VERSION ""

NS_ :

BS_:

BU_: Vector__XXX

BO_ 2021 RES_LSS_Rx: 8 Vector__XXX

BO_ 2020 RES_LSS_Tx: 8 Vector__XXX

BO_ 1553 RES_SDO_Rx: 8 Vector__XXX

BO_ 1425 RES_SDO_Tx: 8 Vector__XXX

BO_ 529 RES_PDO_Rx: 8 Vector__XXX

BO_ 256 RES_TimeStamp: 6 Vector__XXX
SG_ TimeOfDay : 0|48@1+ (1,0) [0|281474976710655] "" Vector__XXX

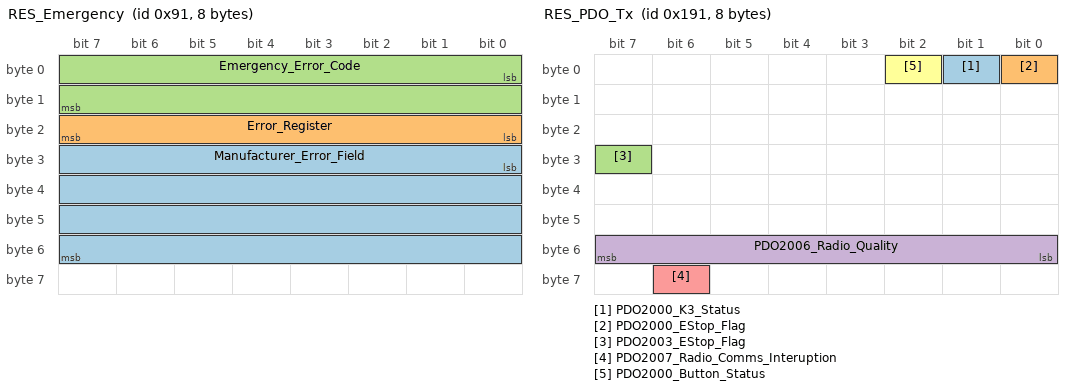
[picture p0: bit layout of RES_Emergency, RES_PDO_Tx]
BO_ 145 RES_Emergency: 8 Vector__XXX
SG_ Manufacturer_Error_Field : 24|32@1+ (1,0) [0|4294967295] "" Vector__XXX
SG_ Error_Register : 16|8@1+ (1,0) [0|255] "" Vector__XXX
SG_ Emergency_Error_Code : 0|16@1+ (1,0) [0|65535] "" Vector__XXX

BO_ 128 RES_Sync: 1 Vector__XXX
SG_ Sync_Counter : 0|8@1+ (1,0) [0|255] "" Vector__XXX

BO_ 1809 RES_NMT_Node_Monitoring: 1 Vector__XXX
SG_ Initialisation_Signalisation : 0|8@1+ (1,0) [0|255] "" Vector__XXX

BO_ 0 RES_NMT_Node_Control: 2 Vector__XXX
SG_ NMT_Node_ID : 8|8@1+ (1,0) [0|255] "" Vector__XXX
SG_ Operational_Mode_Flag : 0|8@1+ (1,0) [0|255] "" Vector__XXX

BO_ 401 RES_PDO_Tx: 8 Vector__XXX
SG_ PDO2000_K3_Status : 1|1@1+ (1,0) [0|1] "" Vector__XXX
SG_ PDO2000_EStop_Flag : 0|1@1+ (1,0) [0|1] "" Vector__XXX
SG_ PDO2003_EStop_Flag : 31|1@1+ (1,0) [0|1] "" Vector__XXX
SG_ PDO2006_Radio_Quality : 48|8@1+ (1,0) [0|255] "%" Vector__XXX
SG_ PDO2007_Radio_Comms_Interuption : 62|1@1+ (1,0) [0|1] "" Vector__XXX
SG_ PDO2000_Button_Status : 2|1@1+ (1,0) [0|1] "" Vector__XXX

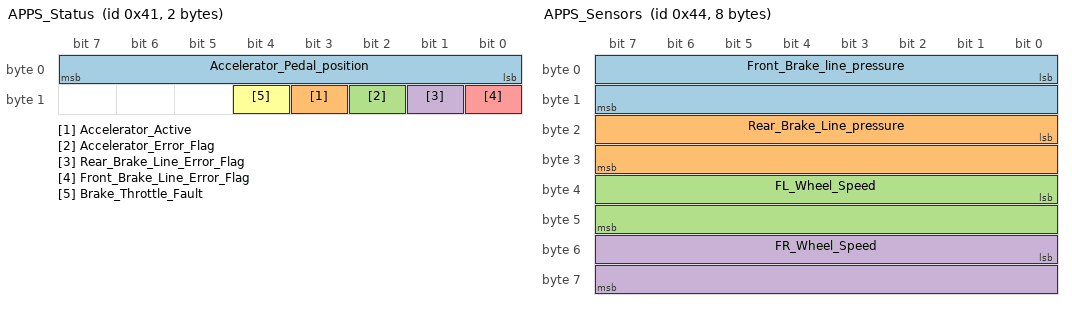
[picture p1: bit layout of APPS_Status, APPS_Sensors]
BO_ 65 APPS_Status: 2 Vector__XXX
SG_ Accelerator_Pedal_position : 0|8@1+ (1,0) [0|255] "%" Vector__XXX
SG_ Accelerator_Active : 11|1@1+ (1,0) [0|1] "" Vector__XXX
SG_ Accelerator_Error_Flag : 10|1@1+ (1,0) [0|1] "" Vector__XXX
SG_ Rear_Brake_Line_Error_Flag : 9|1@1+ (1,0) [0|1] "" Vector__XXX
SG_ Front_Brake_Line_Error_Flag : 8|1@1+ (1,0) [0|1] "" Vector__XXX
SG_ Brake_Throttle_Fault : 12|1@1+ (1,0) [0|1] "" Vector__XXX

BO_ 68 APPS_Sensors: 8 Vector__XXX
SG_ Front_Brake_line_pressure : 0|16@1+ (1,0) [0|32767] "bar" Vector__XXX
SG_ Rear_Brake_Line_pressure : 16|16@1+ (1,0) [0|65535] "bar" Vector__XXX
SG_ FL_Wheel_Speed : 32|16@1+ (0.1,0) [0|6553.5] "rpm" Vector__XXX
SG_ FR_Wheel_Speed : 48|16@1+ (0.1,0) [0|6553.5] "rpm" Vector__XXX

BO_ 66 VCUIO_Wheel_Speeds: 4 Vector__XXX
SG_ RL_Wheel_Speed : 0|16@1+ (0.1,0) [0|6553.5] "rpm" Vector__XXX
SG_ RR_Wheel_Speed : 16|16@1+ (0.1,0) [0|6553.5] "rpm" Vector__XXX

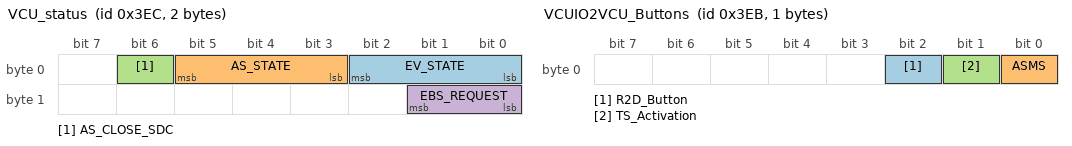
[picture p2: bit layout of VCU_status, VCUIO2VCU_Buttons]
BO_ 1004 VCU_status: 2 Vector__XXX
SG_ EV_STATE : 0|3@1+ (1,0) [0|7] "" Vector__XXX
SG_ AS_STATE : 3|3@1+ (1,0) [0|7] "" Vector__XXX
SG_ AS_CLOSE_SDC : 6|1@1+ (1,0) [0|1] "" Vector__XXX
SG_ EBS_REQUEST : 8|2@1+ (1,0) [0|3] "" Vector__XXX

BO_ 513 Inverter_Snd: 4 Vector__XXX
SG_ Inverter_Snd_Mux M : 0|8@1+ (1,0) [0|0] "" Vector__XXX
SG_ Speed_Request m49 : 8|8@1- (1,0) [-128|127] "" Vector__XXX
SG_ Torque_Request m144 : 8|8@1- (1,0) [-128|127] "" Vector__XXX
SG_ Set_kern_mode m81 : 8|8@1- (1,0) [-128|127] "" Vector__XXX
SG_ Read_cmd m61 : 8|8@1- (1,0) [-128|127] "" Vector__XXX

BO_ 385 Inveter_Rcv: 4 Vector__XXX
SG_ Inveter_Rcv_Mux M : 0|8@1+ (1,0) [0|0] "" Vector__XXX
SG_ Actual_Torque m160 : 8|8@1- (1,0) [-128|127] "" Vector__XXX
SG_ IO_Bitmap m216 : 8|16@1- (1,0) [-32768|32767] "" Vector__XXX
SG_ GO_Drive_Enabled m227 : 8|1@1+ (1,0) [0|1] "" Vector__XXX
SG_ RDY m226 : 8|1@1+ (1,0) [0|1] "" Vector__XXX
SG_ RUN m232 : 8|1@1+ (1,0) [0|1] "" Vector__XXX
SG_ N_Actual m48 : 8|16@1- (1,0) [0|255] "" Vector__XXX
SG_ Kern_Mode m81 : 8|8@1- (1,0) [-128|127] "" Vector__XXX

BO_ 1003 VCUIO2VCU_Buttons: 1 Vector__XXX
SG_ R2D_Button : 2|1@1+ (1,0) [0|1] "" Vector__XXX
SG_ ASMS : 0|1@1+ (1,0) [0|1] "" Vector__XXX
SG_ TS_Activation : 1|1@1+ (1,0) [0|1] "" Vector__XXX

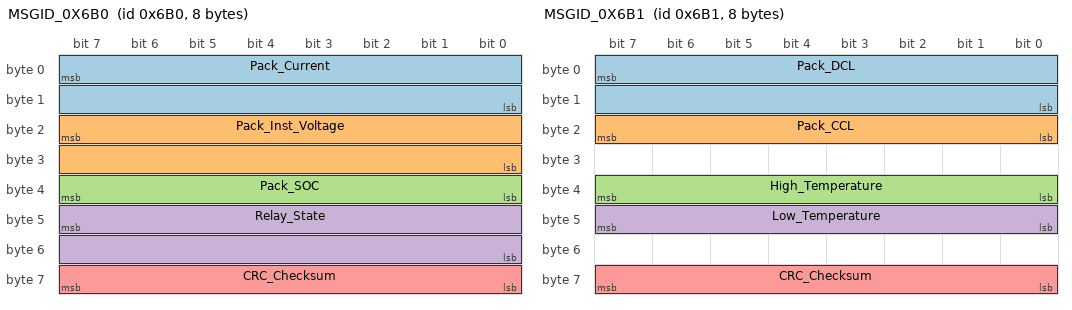
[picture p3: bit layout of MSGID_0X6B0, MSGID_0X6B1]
BO_ 1712 MSGID_0X6B0: 8 Vector__XXX
SG_ Pack_Current : 7|16@0+ (0.1,0) [0|6553.5] "Amps" Vector__XXX
SG_ Pack_Inst_Voltage : 23|16@0+ (0.1,0) [0|6553.5] "Volts" Vector__XXX
SG_ Pack_SOC : 39|8@0+ (0.5,0) [0|127.5] "Percent" Vector__XXX
SG_ Relay_State : 47|16@0+ (1,0) [0|65535] "" Vector__XXX
SG_ CRC_Checksum : 63|8@0+ (1,1720) [1720|1720] "" Vector__XXX

BO_ 1713 MSGID_0X6B1: 8 Vector__XXX
SG_ Pack_DCL : 7|16@0+ (1,0) [0|65535] "Amps" Vector__XXX
SG_ Pack_CCL : 23|8@0+ (1,0) [0|255] "Amps" Vector__XXX
SG_ High_Temperature : 39|8@0+ (1,0) [0|255] "Celsius" Vector__XXX
SG_ Low_Temperature : 47|8@0+ (1,0) [0|255] "Celsius" Vector__XXX
SG_ CRC_Checksum : 63|8@0+ (1,1721) [1721|1721] "" Vector__XXX

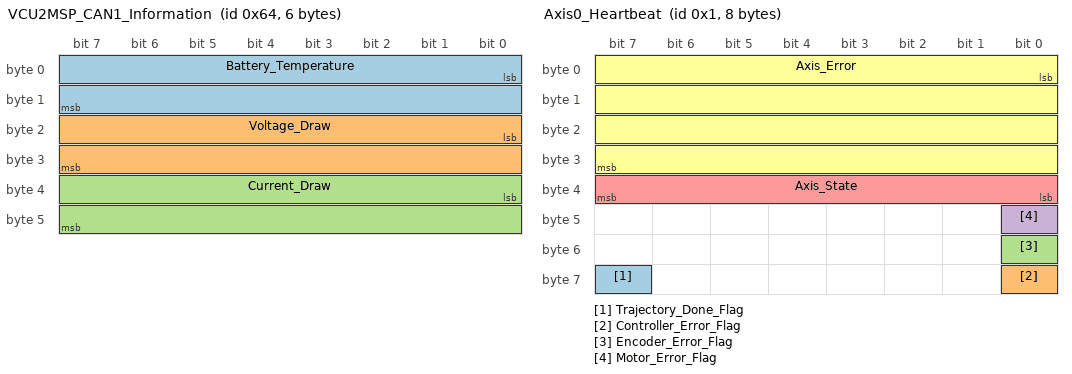
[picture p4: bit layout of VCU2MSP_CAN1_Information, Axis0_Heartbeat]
BO_ 100 VCU2MSP_CAN1_Information: 6 Vector__XXX
SG_ Battery_Temperature : 0|16@1- (1,0) [-32768|32767] "degC" Vector__XXX
SG_ Voltage_Draw : 16|16@1- (0.1,0) [-3276.8|3276.7] "V" Vector__XXX
SG_ Current_Draw : 32|16@1- (0.1,0) [-3276.8|3276.7] "A" Vector__XXX

BO_ 64 MSP2VCU_Status: 1 Vector__XXX
SG_ AMI_STATE : 0|4@1+ (1,0) [0|15] "" Vector__XXX

BO_ 1 Axis0_Heartbeat: 8 Vector__XXX
SG_ Trajectory_Done_Flag : 63|1@1+ (1,0) [0|1] "" Vector__XXX
SG_ Controller_Error_Flag : 56|1@1+ (1,0) [0|1] "" Vector__XXX
SG_ Encoder_Error_Flag : 48|1@1+ (1,0) [0|1] "" Vector__XXX
SG_ Motor_Error_Flag : 40|1@1+ (1,0) [0|1] "" Vector__XXX
SG_ Axis_State : 32|8@1+ (1,0) [0|255] "" Vector__XXX
SG_ Axis_Error : 0|32@1+ (1,0) [0|4294967295] "" Vector__XXX

BO_ 3 Axis0_Get_Motor_Error: 8 Vector__XXX
SG_ Motor_Error : 0|32@1+ (1,0) [0|4294967295] "" Vector__XXX

BO_ 4 Axis0_Get_Encoder_Error: 8 Vector__XXX
SG_ Encoder_Error : 0|32@1+ (1,0) [0|4294967295] "" Vector__XXX

BO_ 5 Axis0_Get_Sensorless_Error: 8 Vector__XXX
SG_ Sensorless_Error : 0|32@1+ (1,0) [0|4294967295] "" Vector__XXX

BO_ 6 Axis0_Set_Axis_Node_ID: 8 Vector__XXX
SG_ Axis_Node_ID : 0|32@1+ (1,0) [0|4294967295] "" Vector__XXX

BO_ 7 Axis0_Set_Axis_State: 8 Vector__XXX
SG_ Axis_Requested_State : 0|32@1+ (1,0) [0|4294967295] "" Vector__XXX

BO_ 9 Axis0_Get_Encoder_Estimates: 8 Vector__XXX
SG_ Vel_Estimate : 32|32@1- (1,0) [-3.4E038|3.4E038] "rev/s" Vector__XXX
SG_ Pos_Estimate : 0|32@1- (1,0) [-3.4E038|3.4E038] "rev" Vector__XXX

BO_ 10 Axis0_Get_Encoder_Count: 8 Vector__XXX
SG_ Count_in_CPR : 32|32@1+ (1,0) [0|4294967295] "counts" Vector__XXX
SG_ Shadow_Count : 0|32@1+ (1,0) [0|4294967295] "counts" Vector__XXX

BO_ 11 Axis0_Set_Controller_Mode: 8 Vector__XXX
SG_ Input_Mode : 32|32@1+ (1,0) [0|4294967295] "" Vector__XXX
SG_ Control_Mode : 0|32@1+ (1,0) [0|4294967295] "" Vector__XXX

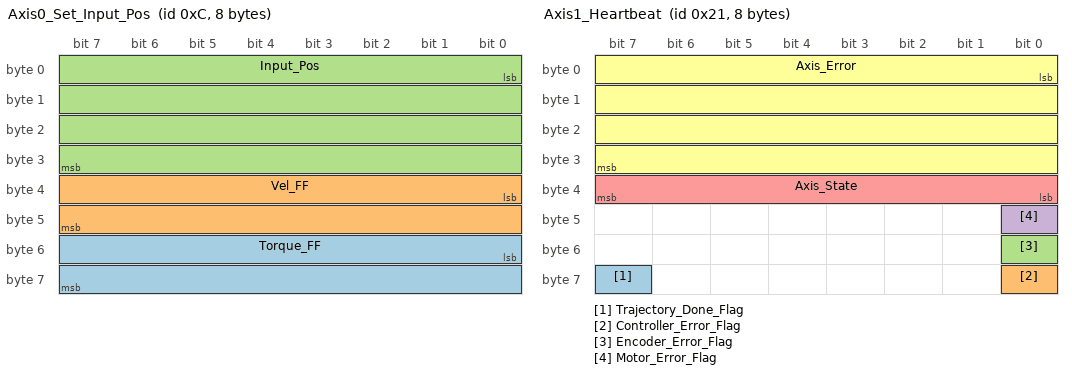
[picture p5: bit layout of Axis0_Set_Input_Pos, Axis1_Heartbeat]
BO_ 12 Axis0_Set_Input_Pos: 8 Vector__XXX
SG_ Torque_FF : 48|16@1- (0.001,0) [-32.768|32.767] "Nm" Vector__XXX
SG_ Vel_FF : 32|16@1- (0.001,0) [-32.768|32.767] "rev/s" Vector__XXX
SG_ Input_Pos : 0|32@1- (1,0) [-3.4E038|3.4E038] "rev" Vector__XXX

BO_ 13 Axis0_Set_Input_Vel: 8 Vector__XXX
SG_ Input_Torque_FF : 32|32@1- (1,0) [-3.4E038|3.4E038] "rev/s" Vector__XXX
SG_ Input_Vel : 0|32@1- (1,0) [-3.4E038|3.4E038] "rev" Vector__XXX

BO_ 14 Axis0_Set_Input_Torque: 8 Vector__XXX
SG_ Input_Torque : 0|32@1- (1,0) [-3.4E038|3.4E038] "Nm" Vector__XXX

BO_ 15 Axis0_Set_Limits: 8 Vector__XXX
SG_ Current_Limit : 32|32@1- (1,0) [-3.4E038|3.4E038] "A" Vector__XXX
SG_ Velocity_Limit : 0|32@1- (1,0) [-3.4E038|3.4E038] "rev/s" Vector__XXX

BO_ 16 Axis0_Start_Anticogging: 0 Vector__XXX

BO_ 17 Axis0_Set_Traj_Vel_Limit: 8 Vector__XXX
SG_ Traj_Vel_Limit : 0|32@1- (1,0) [-3.4E038|3.4E038] "rev/s" Vector__XXX

BO_ 18 Axis0_Set_Traj_Accel_Limits: 8 Vector__XXX
SG_ Traj_Decel_Limit : 32|32@1- (1,0) [-3.4E038|3.4E038] "rev/s^2" Vector__XXX
SG_ Traj_Accel_Limit : 0|32@1- (1,0) [-3.4E038|3.4E038] "rev/s^2" Vector__XXX

BO_ 19 Axis0_Set_Traj_Inertia: 8 Vector__XXX
SG_ Traj_Inertia : 0|32@1- (1,0) [-3.4E038|3.4E038] "Nm / (rev/s^2)" Vector__XXX

BO_ 20 Axis0_Get_Iq: 8 Vector__XXX
SG_ Iq_Measured : 32|32@1- (1,0) [-3.4E038|3.4E038] "A" Vector__XXX
SG_ Iq_Setpoint : 0|32@1- (1,0) [-3.4E038|3.4E038] "A" Vector__XXX

BO_ 21 Axis0_Get_Sensorless_Estimates: 8 Vector__XXX
SG_ Sensorless_Vel_Estimate : 32|32@1- (1,0) [-3.4E038|3.4E038] "rev/s" Vector__XXX
SG_ Sensorless_Pos_Estimate : 0|32@1- (1,0) [-3.4E038|3.4E038] "rev" Vector__XXX

BO_ 22 Axis0_Reboot: 0 Vector__XXX

BO_ 23 Axis0_Get_Bus_Voltage_Current: 8 Vector__XXX
SG_ Bus_Current : 32|32@1- (1,0) [-3.4E038|3.4E038] "A" Vector__XXX
SG_ Bus_Voltage : 0|32@1- (1,0) [-3.4E038|3.4E038] "V" Vector__XXX

BO_ 24 Axis0_Clear_Errors: 0 Vector__XXX

BO_ 25 Axis0_Set_Linear_Count: 8 Vector__XXX
SG_ Position : 0|32@1- (1,0) [-2147483648|2147483647] "counts" Vector__XXX

BO_ 26 Axis0_Set_Pos_Gain: 8 Vector__XXX
SG_ Pos_Gain : 0|32@1- (1,0) [-3.4E038|3.4E038] "(rev/s) / rev" Vector__XXX

BO_ 27 Axis0_Set_Vel_Gains: 8 Vector__XXX
SG_ Vel_Integrator_Gain : 32|32@1- (1,0) [-3.4E038|3.4E038] "(Nm / (rev/s)) /" Vector__XXX
SG_ Vel_Gain : 0|32@1- (1,0) [-3.4E038|3.4E038] "Nm / (rev/s)" Vector__XXX

BO_ 28 Axis0_Get_ADC_Voltage: 8 Vector__XXX
SG_ ADC_Voltage : 0|32@1- (1,0) [-3.4E038|3.4E038] "V" Vector__XXX

BO_ 29 Axis0_Get_Controller_Error: 8 Vector__XXX
SG_ Controller_Error : 0|32@1+ (1,0) [0|4294967295] "" Vector__XXX

BO_ 33 Axis1_Heartbeat: 8 Vector__XXX
SG_ Trajectory_Done_Flag : 63|1@1+ (1,0) [0|1] "" Vector__XXX
SG_ Controller_Error_Flag : 56|1@1+ (1,0) [0|1] "" Vector__XXX
SG_ Encoder_Error_Flag : 48|1@1+ (1,0) [0|1] "" Vector__XXX
SG_ Motor_Error_Flag : 40|1@1+ (1,0) [0|1] "" Vector__XXX
SG_ Axis_State : 32|8@1+ (1,0) [0|255] "" Vector__XXX
SG_ Axis_Error : 0|32@1+ (1,0) [0|4294967295] "" Vector__XXX

BO_ 35 Axis1_Get_Motor_Error: 8 Vector__XXX
SG_ Motor_Error : 0|32@1+ (1,0) [0|4294967295] "" Vector__XXX

BO_ 36 Axis1_Get_Encoder_Error: 8 Vector__XXX
SG_ Encoder_Error : 0|32@1+ (1,0) [0|4294967295] "" Vector__XXX

BO_ 37 Axis1_Get_Sensorless_Error: 8 Vector__XXX
SG_ Sensorless_Error : 0|32@1+ (1,0) [0|4294967295] "" Vector__XXX

BO_ 38 Axis1_Set_Axis_Node_ID: 8 Vector__XXX
SG_ Axis_Node_ID : 0|32@1+ (1,0) [0|4294967295] "" Vector__XXX

BO_ 39 Axis1_Set_Axis_State: 8 Vector__XXX
SG_ Axis_Requested_State : 0|32@1+ (1,0) [0|4294967295] "" Vector__XXX

BO_ 41 Axis1_Get_Encoder_Estimates: 8 Vector__XXX
SG_ Vel_Estimate : 32|32@1- (1,0) [-3.4E038|3.4E038] "rev/s" Vector__XXX
SG_ Pos_Estimate : 0|32@1- (1,0) [-3.4E038|3.4E038] "rev" Vector__XXX

BO_ 42 Axis1_Get_Encoder_Count: 8 Vector__XXX
SG_ Count_in_CPR : 32|32@1+ (1,0) [0|4294967295] "counts" Vector__XXX
SG_ Shadow_Count : 0|32@1+ (1,0) [0|4294967295] "counts" Vector__XXX

BO_ 43 Axis1_Set_Controller_Mode: 8 Vector__XXX
SG_ Input_Mode : 32|32@1+ (1,0) [0|4294967295] "" Vector__XXX
SG_ Control_Mode : 0|32@1+ (1,0) [0|4294967295] "" Vector__XXX

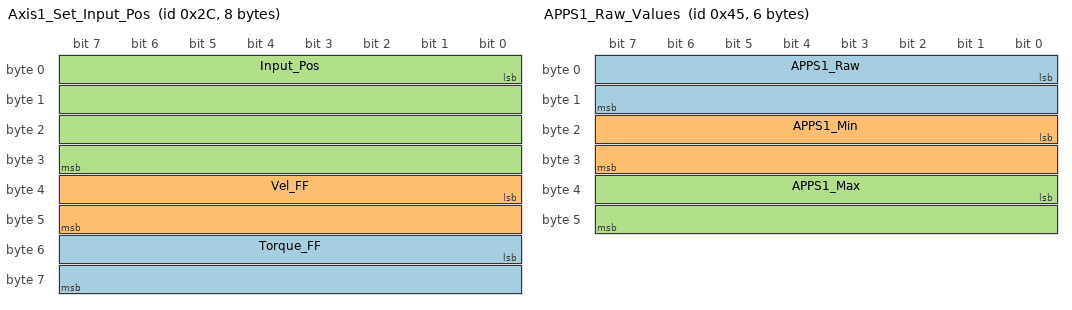
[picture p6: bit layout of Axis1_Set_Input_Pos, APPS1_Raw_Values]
BO_ 44 Axis1_Set_Input_Pos: 8 Vector__XXX
SG_ Torque_FF : 48|16@1- (0.001,0) [-32.768|32.767] "Nm" Vector__XXX
SG_ Vel_FF : 32|16@1- (0.001,0) [-32.768|32.767] "rev/s" Vector__XXX
SG_ Input_Pos : 0|32@1- (1,0) [-3.4E038|3.4E038] "rev" Vector__XXX

BO_ 45 Axis1_Set_Input_Vel: 8 Vector__XXX
SG_ Input_Torque_FF : 32|32@1- (1,0) [-3.4E038|3.4E038] "rev/s" Vector__XXX
SG_ Input_Vel : 0|32@1- (1,0) [-3.4E038|3.4E038] "rev" Vector__XXX

BO_ 46 Axis1_Set_Input_Torque: 8 Vector__XXX
SG_ Input_Torque : 0|32@1- (1,0) [-3.4E038|3.4E038] "Nm" Vector__XXX

BO_ 47 Axis1_Set_Limits: 8 Vector__XXX
SG_ Current_Limit : 32|32@1- (1,0) [-3.4E038|3.4E038] "A" Vector__XXX
SG_ Velocity_Limit : 0|32@1- (1,0) [-3.4E038|3.4E038] "rev/s" Vector__XXX

BO_ 48 Axis1_Start_Anticogging: 0 Vector__XXX

BO_ 49 Axis1_Set_Traj_Vel_Limit: 8 Vector__XXX
SG_ Traj_Vel_Limit : 0|32@1- (1,0) [-3.4E038|3.4E038] "rev/s" Vector__XXX

BO_ 50 Axis1_Set_Traj_Accel_Limits: 8 Vector__XXX
SG_ Traj_Decel_Limit : 32|32@1- (1,0) [-3.4E038|3.4E038] "rev/s^2" Vector__XXX
SG_ Traj_Accel_Limit : 0|32@1- (1,0) [-3.4E038|3.4E038] "rev/s^2" Vector__XXX

BO_ 51 Axis1_Set_Traj_Inertia: 8 Vector__XXX
SG_ Traj_Inertia : 0|32@1- (1,0) [-3.4E038|3.4E038] "Nm / (rev/s^2)" Vector__XXX

BO_ 52 Axis1_Get_Iq: 8 Vector__XXX
SG_ Iq_Measured : 32|32@1- (1,0) [-3.4E038|3.4E038] "A" Vector__XXX
SG_ Iq_Setpoint : 0|32@1- (1,0) [-3.4E038|3.4E038] "A" Vector__XXX

BO_ 53 Axis1_Get_Sensorless_Estimates: 8 Vector__XXX
SG_ Sensorless_Vel_Estimate : 32|32@1- (1,0) [-3.4E038|3.4E038] "rev/s" Vector__XXX
SG_ Sensorless_Pos_Estimate : 0|32@1- (1,0) [-3.4E038|3.4E038] "rev" Vector__XXX

BO_ 54 Axis1_Reboot: 0 Vector__XXX

BO_ 55 Axis1_Get_Bus_Voltage_Current: 8 Vector__XXX
SG_ Bus_Current : 32|32@1- (1,0) [-3.4E038|3.4E038] "A" Vector__XXX
SG_ Bus_Voltage : 0|32@1- (1,0) [-3.4E038|3.4E038] "V" Vector__XXX

BO_ 56 Axis1_Clear_Errors: 0 Vector__XXX

BO_ 57 Axis1_Set_Linear_Count: 8 Vector__XXX
SG_ Position : 0|32@1- (1,0) [-2147483648|2147483647] "counts" Vector__XXX

BO_ 58 Axis1_Set_Pos_Gain: 8 Vector__XXX
SG_ Pos_Gain : 0|32@1- (1,0) [-3.4E038|3.4E038] "(rev/s) / rev" Vector__XXX

BO_ 59 Axis1_Set_Vel_Gains: 8 Vector__XXX
SG_ Vel_Integrator_Gain : 32|32@1- (1,0) [-3.4E038|3.4E038] "(Nm / (rev/s)) /" Vector__XXX
SG_ Vel_Gain : 0|32@1- (1,0) [-3.4E038|3.4E038] "Nm / (rev/s)" Vector__XXX

BO_ 60 Axis1_Get_ADC_Voltage: 8 Vector__XXX
SG_ ADC_Voltage : 0|32@1- (1,0) [-3.4E038|3.4E038] "V" Vector__XXX

BO_ 61 Axis1_Get_Controller_Error: 8 Vector__XXX
SG_ Controller_Error : 0|32@1+ (1,0) [0|4294967295] "" Vector__XXX

BO_ 67 APPS_Config: 1 Vector__XXX
SG_ APPS_RAW_ENABLE : 0|1@1+ (1,0) [0|1] "" Vector__XXX
SG_ SERIAL_DEBUG_ENABLE : 1|1@1+ (1,0) [0|1] "" Vector__XXX

BO_ 69 APPS1_Raw_Values: 6 Vector__XXX
SG_ APPS1_Raw : 0|16@1+ (1,0) [0|65535] "" Vector__XXX
SG_ APPS1_Min : 16|16@1+ (1,0) [0|65535] "" Vector__XXX
SG_ APPS1_Max : 32|16@1+ (1,0) [0|65535] "" Vector__XXX

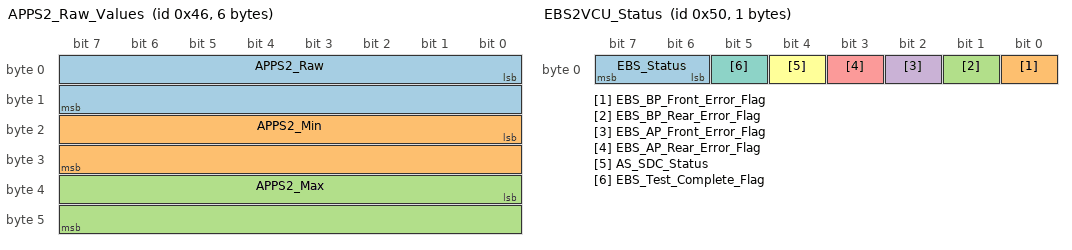
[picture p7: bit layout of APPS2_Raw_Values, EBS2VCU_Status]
BO_ 70 APPS2_Raw_Values: 6 Vector__XXX
SG_ APPS2_Raw : 0|16@1+ (1,0) [0|65535] "" Vector__XXX
SG_ APPS2_Min : 16|16@1+ (1,0) [0|65535] "" Vector__XXX
SG_ APPS2_Max : 32|16@1+ (1,0) [0|65535] "" Vector__XXX

BO_ 71 APPS1_Setup: 4 Vector__XXX
SG_ Set_APPS1_Min : 0|16@1+ (1,0) [0|65535] "" Vector__XXX
SG_ Set_APPS1_Max : 16|16@1+ (1,0) [0|65535] "" Vector__XXX

BO_ 72 APPS2_Setup: 4 Vector__XXX
SG_ Set_APPS2_Min : 0|16@1+ (1,0) [0|65535] "" Vector__XXX
SG_ Set_APPS2_Max : 16|16@1+ (1,0) [0|65535] "" Vector__XXX

BO_ 80 EBS2VCU_Status: 1 Vector__XXX
SG_ EBS_Status : 6|2@1+ (1,0) [0|3] "" Vector__XXX
SG_ EBS_BP_Front_Error_Flag : 0|1@1+ (1,0) [0|1] "" Vector__XXX
SG_ EBS_BP_Rear_Error_Flag : 1|1@1+ (1,0) [0|1] "" Vector__XXX
SG_ EBS_AP_Front_Error_Flag : 2|1@1+ (1,0) [0|1] "" Vector__XXX
SG_ EBS_AP_Rear_Error_Flag : 3|1@1+ (1,0) [0|1] "" Vector__XXX
SG_ AS_SDC_Status : 4|1@1+ (1,0) [0|1] "" Vector__XXX
SG_ EBS_Test_Complete_Flag : 5|1@1+ (1,0) [0|1] "" Vector__XXX

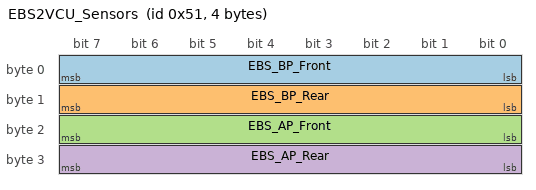
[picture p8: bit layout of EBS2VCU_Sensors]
BO_ 81 EBS2VCU_Sensors: 4 Vector__XXX
SG_ EBS_BP_Front : 0|8@1+ (1,0) [0|255] "Bar" Vector__XXX
SG_ EBS_BP_Rear : 8|8@1+ (1,0) [0|255] "Bar" Vector__XXX
SG_ EBS_AP_Front : 16|8@1+ (1,0) [0|255] "" Vector__XXX
SG_ EBS_AP_Rear : 24|8@1+ (1,0) [0|255] "" Vector__XXX

CM_ SG_ 401 PDO2000_K3_Status "RES Go Flag";
CM_ SG_ 401 PDO2000_EStop_Flag "K2 - RES EStop Status";
CM_ SG_ 401 PDO2003_EStop_Flag "K2 - RES Go Status";
CM_ SG_ 401 PDO2000_Button_Status "Black Button Press Status";
CM_ SG_ 65 Accelerator_Active "APPS sending current requests";
CM_ SG_ 68 FL_Wheel_Speed "Front Left Wheel Speed";
CM_ SG_ 68 FR_Wheel_Speed "Front Right Wheel Speed";
CM_ SG_ 1003 R2D_Button "R2D dashboard button state";
CM_ SG_ 1003 ASMS "State of ASMS (Master Switch)";
CM_ BO_ 1712 "This ID Transmits at 8 ms.";
CM_ BO_ 1713 "This ID Transmits at 104 ms.";
CM_ SG_ 100 Battery_Temperature "Battery temperature measured by the BMS";
CM_ SG_ 100 Voltage_Draw "Voltage draw measured by the BMS";
CM_ SG_ 100 Current_Draw "Currentdraw measured by the BMS";
CM_ SG_ 64 AMI_STATE "State of the Mission Indicator";
CM_ SG_ 67 APPS_RAW_ENABLE "Sets APPS to send raw sensor values";
CM_ SG_ 67 SERIAL_DEBUG_ENABLE "Enables and disables serial debug on the APPS MCU";

BA_DEF_  "BusType" STRING ;
BA_DEF_ BO_  "GenMsgCycleTime" INT 0 65535;
BA_DEF_ SG_  "GenSigStartValue" FLOAT -3.4E+038 3.4E+038;

BA_DEF_DEF_  "BusType" "CAN";
BA_DEF_DEF_  "GenMsgCycleTime" 0;
BA_DEF_DEF_  "GenSigStartValue" 0;

BA_ "GenMsgCycleTime" BO_ 1 100;
BA_ "GenMsgCycleTime" BO_ 9 10;
BA_ "GenMsgCycleTime" BO_ 33 100;
BA_ "GenMsgCycleTime" BO_ 41 10;

BA_ "GenSigStartValue" SG_ 1712 CRC_Checksum 1720;
BA_ "GenSigStartValue" SG_ 1713 CRC_Checksum 1721;

VAL_ 513 Inverter_Snd_Mux 49 "Send_mux_49" 144 "Send_mux_144" 81 "Send_mux_81" 61 "Send_mux_61";
VAL_ 385 Inveter_Rcv_Mux 160 "Inv_Rcv_Mux_160" 216 "Inv_Rcv_Mux_216" 227 "Inv_Rcv_Mux_227" 226 "Inv_Rcv_Mux_226" 232 "Inv_Rcv_Mux_232" 48 "Inv_Rcv_Mux_48" 81 "Inv_Rcv_Mux_81";
VAL_ 1004 EV_STATE 1 "TS_OFF" 2 "TS_ACTIVE" 3 "MANUAL" 4 "AUTONOMOUS_DRIVING" 7 "CORSA_MODE";
VAL_ 1004 AS_STATE 1 "OFF" 2 "READY" 3 "DRIVING" 4 "EMERGENCY" 5 "AS_FINISHED";
VAL_ 1004 EBS_REQUEST 0 "Off" 1 "On" 2 "Test";
VAL_ 64 AMI_STATE 0 "NOT SELECTED" 1 "ACCELERATION" 2 "SKIDPAD" 3 "AUTOCROSS" 4 "TRACK DRIVE" 5 "STATIC INSPECTION A" 6 "STATIC INSPECTION B" 7 "AUTONOMOUS DEMO" 8 "EBS TEST";
VAL_ 1 Axis_State 0 "UNDEFINED" 1 "IDLE" 2 "STARTUP_SEQUENCE" 3 "FULL_CALIBRATION_SEQUENCE" 4 "MOTOR_CALIBRATION" 6 "ENCODER_INDEX_SEARCH" 7 "ENCODER_OFFSET_CALIBRATION" 8 "CLOSED_LOOP_CONTROL" 9 "LOCKIN_SPIN" 10 "ENCODER_DIR_FIND" 11 "HOMING" 12 "ENCODER_HALL_POLARITY_CALIBRATION" 13 "ENCODER_HALL_PHASE_CALIBRATION";
VAL_ 1 Axis_Error 0 "NONE" 1 "INVALID_STATE" 64 "MOTOR_FAILED" 128 "SENSORLESS_ESTIMATOR_FAILED" 256 "ENCODER_FAILED" 512 "CONTROLLER_FAILED" 2048 "WATCHDOG_TIMER_EXPIRED" 4096 "MIN_ENDSTOP_PRESSED" 8192 "MAX_ENDSTOP_PRESSED" 16384 "ESTOP_REQUESTED" 131072 "HOMING_WITHOUT_ENDSTOP" 262144 "OVER_TEMP" 524288 "UNKNOWN_POSITION";
VAL_ 3 Motor_Error 0 "NONE" 1 "PHASE_RESISTANCE_OUT_OF_RANGE" 2 "PHASE_INDUCTANCE_OUT_OF_RANGE" 8 "DRV_FAULT" 16 "CONTROL_DEADLINE_MISSED" 128 "MODULATION_MAGNITUDE" 1024 "CURRENT_SENSE_SATURATION" 4096 "CURRENT_LIMIT_VIOLATION" 65536 "MODULATION_IS_NAN" 131072 "MOTOR_THERMISTOR_OVER_TEMP" 262144 "FET_THERMISTOR_OVER_TEMP" 524288 "TIMER_UPDATE_MISSED" 1048576 "CURRENT_MEASUREMENT_UNAVAILABLE" 2097152 "CONTROLLER_FAILED" 4194304 "I_BUS_OUT_OF_RANGE" 8388608 "BRAKE_RESISTOR_DISARMED" 16777216 "SYSTEM_LEVEL" 33554432 "BAD_TIMING" 67108864 "UNKNOWN_PHASE_ESTIMATE" 134217728 "UNKNOWN_PHASE_VEL" 268435456 "UNKNOWN_TORQUE" 536870912 "UNKNOWN_CURRENT_COMMAND" 1073741824 "UNKNOWN_CURRENT_MEASUREMENT" -2147483648 "UNKNOWN_VBUS_VOLTAGE" 0 "UNKNOWN_VOLTAGE_COMMAND" 0 "UNKNOWN_GAINS" 0 "CONTROLLER_INITIALIZING" 0 "UNBALANCED_PHASES";
VAL_ 4 Encoder_Error 0 "NONE" 1 "UNSTABLE_GAIN" 2 "CPR_POLEPAIRS_MISMATCH" 4 "NO_RESPONSE" 8 "UNSUPPORTED_ENCODER_MODE" 16 "ILLEGAL_HALL_STATE" 32 "INDEX_NOT_FOUND_YET" 64 "ABS_SPI_TIMEOUT" 128 "ABS_SPI_COM_FAIL" 256 "ABS_SPI_NOT_READY" 512 "HALL_NOT_CALIBRATED_YET";
VAL_ 5 Sensorless_Error 0 "NONE" 1 "UNSTABLE_GAIN" 2 "UNKNOWN_CURRENT_MEASUREMENT";
VAL_ 7 Axis_Requested_State 0 "UNDEFINED" 1 "IDLE" 2 "STARTUP_SEQUENCE" 3 "FULL_CALIBRATION_SEQUENCE" 4 "MOTOR_CALIBRATION" 6 "ENCODER_INDEX_SEARCH" 7 "ENCODER_OFFSET_CALIBRATION" 8 "CLOSED_LOOP_CONTROL" 9 "LOCKIN_SPIN" 10 "ENCODER_DIR_FIND" 11 "HOMING" 12 "ENCODER_HALL_POLARITY_CALIBRATION" 13 "ENCODER_HALL_PHASE_CALIBRATION";
VAL_ 11 Input_Mode 0 "INACTIVE" 1 "PASSTHROUGH" 2 "VEL_RAMP" 3 "POS_FILTER" 4 "MIX_CHANNELS" 5 "TRAP_TRAJ" 6 "TORQUE_RAMP" 7 "MIRROR" 8 "TUNING";
VAL_ 11 Control_Mode 0 "VOLTAGE_CONTROL" 1 "TORQUE_CONTROL" 2 "VELOCITY_CONTROL" 3 "POSITION_CONTROL";
VAL_ 29 Controller_Error 0 "NONE" 1 "OVERSPEED" 2 "INVALID_INPUT_MODE" 4 "UNSTABLE_GAIN" 8 "INVALID_MIRROR_AXIS" 16 "INVALID_LOAD_ENCODER" 32 "INVALID_ESTIMATE" 64 "INVALID_CIRCULAR_RANGE" 128 "SPINOUT_DETECTED";
VAL_ 33 Axis_State 0 "UNDEFINED" 1 "IDLE" 2 "STARTUP_SEQUENCE" 3 "FULL_CALIBRATION_SEQUENCE" 4 "MOTOR_CALIBRATION" 6 "ENCODER_INDEX_SEARCH" 7 "ENCODER_OFFSET_CALIBRATION" 8 "CLOSED_LOOP_CONTROL" 9 "LOCKIN_SPIN" 10 "ENCODER_DIR_FIND" 11 "HOMING" 12 "ENCODER_HALL_POLARITY_CALIBRATION" 13 "ENCODER_HALL_PHASE_CALIBRATION";
VAL_ 33 Axis_Error 0 "NONE" 1 "INVALID_STATE" 64 "MOTOR_FAILED" 128 "SENSORLESS_ESTIMATOR_FAILED" 256 "ENCODER_FAILED" 512 "CONTROLLER_FAILED" 2048 "WATCHDOG_TIMER_EXPIRED" 4096 "MIN_ENDSTOP_PRESSED" 8192 "MAX_ENDSTOP_PRESSED" 16384 "ESTOP_REQUESTED" 131072 "HOMING_WITHOUT_ENDSTOP" 262144 "OVER_TEMP" 524288 "UNKNOWN_POSITION";
VAL_ 35 Motor_Error 0 "NONE" 1 "PHASE_RESISTANCE_OUT_OF_RANGE" 2 "PHASE_INDUCTANCE_OUT_OF_RANGE" 8 "DRV_FAULT" 16 "CONTROL_DEADLINE_MISSED" 128 "MODULATION_MAGNITUDE" 1024 "CURRENT_SENSE_SATURATION" 4096 "CURRENT_LIMIT_VIOLATION" 65536 "MODULATION_IS_NAN" 131072 "MOTOR_THERMISTOR_OVER_TEMP" 262144 "FET_THERMISTOR_OVER_TEMP" 524288 "TIMER_UPDATE_MISSED" 1048576 "CURRENT_MEASUREMENT_UNAVAILABLE" 2097152 "CONTROLLER_FAILED" 4194304 "I_BUS_OUT_OF_RANGE" 8388608 "BRAKE_RESISTOR_DISARMED" 16777216 "SYSTEM_LEVEL" 33554432 "BAD_TIMING" 67108864 "UNKNOWN_PHASE_ESTIMATE" 134217728 "UNKNOWN_PHASE_VEL" 268435456 "UNKNOWN_TORQUE" 536870912 "UNKNOWN_CURRENT_COMMAND" 1073741824 "UNKNOWN_CURRENT_MEASUREMENT" -2147483648 "UNKNOWN_VBUS_VOLTAGE" 0 "UNKNOWN_VOLTAGE_COMMAND" 0 "UNKNOWN_GAINS" 0 "CONTROLLER_INITIALIZING" 0 "UNBALANCED_PHASES";
VAL_ 36 Encoder_Error 0 "NONE" 1 "UNSTABLE_GAIN" 2 "CPR_POLEPAIRS_MISMATCH" 4 "NO_RESPONSE" 8 "UNSUPPORTED_ENCODER_MODE" 16 "ILLEGAL_HALL_STATE" 32 "INDEX_NOT_FOUND_YET" 64 "ABS_SPI_TIMEOUT" 128 "ABS_SPI_COM_FAIL" 256 "ABS_SPI_NOT_READY" 512 "HALL_NOT_CALIBRATED_YET";
VAL_ 37 Sensorless_Error 0 "NONE" 1 "UNSTABLE_GAIN" 2 "UNKNOWN_CURRENT_MEASUREMENT";
VAL_ 39 Axis_Requested_State 0 "UNDEFINED" 1 "IDLE" 2 "STARTUP_SEQUENCE" 3 "FULL_CALIBRATION_SEQUENCE" 4 "MOTOR_CALIBRATION" 6 "ENCODER_INDEX_SEARCH" 7 "ENCODER_OFFSET_CALIBRATION" 8 "CLOSED_LOOP_CONTROL" 9 "LOCKIN_SPIN" 10 "ENCODER_DIR_FIND" 11 "HOMING" 12 "ENCODER_HALL_POLARITY_CALIBRATION" 13 "ENCODER_HALL_PHASE_CALIBRATION";
VAL_ 43 Input_Mode 0 "INACTIVE" 1 "PASSTHROUGH" 2 "VEL_RAMP" 3 "POS_FILTER" 4 "MIX_CHANNELS" 5 "TRAP_TRAJ" 6 "TORQUE_RAMP" 7 "MIRROR" 8 "TUNING";
VAL_ 43 Control_Mode 0 "VOLTAGE_CONTROL" 1 "TORQUE_CONTROL" 2 "VELOCITY_CONTROL" 3 "POSITION_CONTROL";
VAL_ 61 Controller_Error 0 "NONE" 1 "OVERSPEED" 2 "INVALID_INPUT_MODE" 4 "UNSTABLE_GAIN" 8 "INVALID_MIRROR_AXIS" 16 "INVALID_LOAD_ENCODER" 32 "INVALID_ESTIMATE" 64 "INVALID_CIRCULAR_RANGE" 128 "SPINOUT_DETECTED";
VAL_ 80 EBS_Status 0 "Off" 1 "On" 2 "Error";

SIG_VALTYPE_ 9 Vel_Estimate : 1;
SIG_VALTYPE_ 9 Pos_Estimate : 1;
SIG_VALTYPE_ 12 Input_Pos : 1;
SIG_VALTYPE_ 13 Input_Torque_FF : 1;
SIG_VALTYPE_ 13 Input_Vel : 1;
SIG_VALTYPE_ 14 Input_Torque : 1;
SIG_VALTYPE_ 15 Current_Limit : 1;
SIG_VALTYPE_ 15 Velocity_Limit : 1;
SIG_VALTYPE_ 17 Traj_Vel_Limit : 1;
SIG_VALTYPE_ 18 Traj_Decel_Limit : 1;
SIG_VALTYPE_ 18 Traj_Accel_Limit : 1;
SIG_VALTYPE_ 19 Traj_Inertia : 1;
SIG_VALTYPE_ 20 Iq_Measured : 1;
SIG_VALTYPE_ 20 Iq_Setpoint : 1;
SIG_VALTYPE_ 21 Sensorless_Vel_Estimate : 1;
SIG_VALTYPE_ 21 Sensorless_Pos_Estimate : 1;
SIG_VALTYPE_ 23 Bus_Current : 1;
SIG_VALTYPE_ 23 Bus_Voltage : 1;
SIG_VALTYPE_ 26 Pos_Gain : 1;
SIG_VALTYPE_ 27 Vel_Integrator_Gain : 1;
SIG_VALTYPE_ 27 Vel_Gain : 1;
SIG_VALTYPE_ 28 ADC_Voltage : 1;
SIG_VALTYPE_ 41 Vel_Estimate : 1;
SIG_VALTYPE_ 41 Pos_Estimate : 1;
SIG_VALTYPE_ 44 Input_Pos : 1;
SIG_VALTYPE_ 45 Input_Torque_FF : 1;
SIG_VALTYPE_ 45 Input_Vel : 1;
SIG_VALTYPE_ 46 Input_Torque : 1;
SIG_VALTYPE_ 47 Current_Limit : 1;
SIG_VALTYPE_ 47 Velocity_Limit : 1;
SIG_VALTYPE_ 49 Traj_Vel_Limit : 1;
SIG_VALTYPE_ 50 Traj_Decel_Limit : 1;
SIG_VALTYPE_ 50 Traj_Accel_Limit : 1;
SIG_VALTYPE_ 51 Traj_Inertia : 1;
SIG_VALTYPE_ 52 Iq_Measured : 1;
SIG_VALTYPE_ 52 Iq_Setpoint : 1;
SIG_VALTYPE_ 53 Sensorless_Vel_Estimate : 1;
SIG_VALTYPE_ 53 Sensorless_Pos_Estimate : 1;
SIG_VALTYPE_ 55 Bus_Current : 1;
SIG_VALTYPE_ 55 Bus_Voltage : 1;
SIG_VALTYPE_ 58 Pos_Gain : 1;
SIG_VALTYPE_ 59 Vel_Integrator_Gain : 1;
SIG_VALTYPE_ 59 Vel_Gain : 1;
SIG_VALTYPE_ 60 ADC_Voltage : 1;
